# PIC32MK1024GPK064 device description
Architecture: MIPS; Family: PIC32MK; Series: PIC32MK
Registers are 32-bit, read-write, no defined reset value unless marked. A register's access mark holds for its fields unless they carry their own. Offsets are from the block's base; [hi:lo] are bit positions; 'fields as' and 'values as' point back to an identical list.

## RTCC
Instances: RTCC 0x1f8c0000 in periph_pb6_std
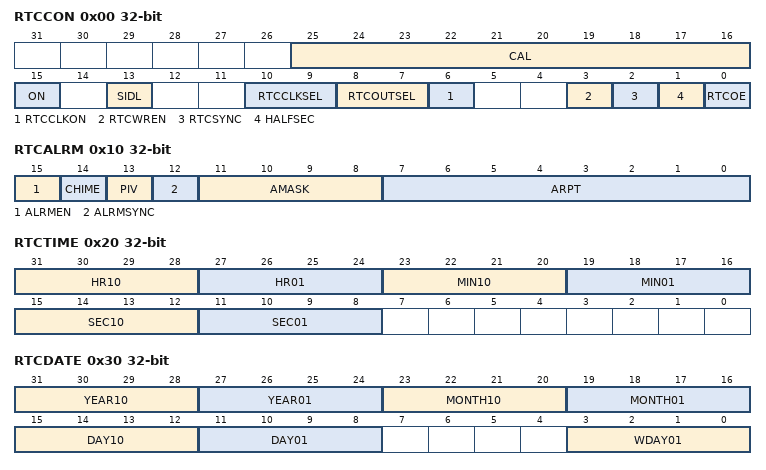
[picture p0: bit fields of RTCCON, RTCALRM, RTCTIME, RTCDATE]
0x00 RTCCON — Real-Time Clock and Calendar Control Register
  [25:16] CAL — Real-Time Clock Drift Calibration bits
    0x1ff=Maximum positive adjustment; 1=Minimum positive adjustment; 0=No adjustment; 0x3ff=Minimum negative adjustment; 0x200=Minimum negative adjustment
  [15] ON — RTCC On bit
    1=RTCC module is enabled; 0=RTCC module is disabled
  [13] SIDL — Stop in Idle Mode bit
    1=Disables RTCC operation when CPU enters Idle mode; 0=Continue normal operation when CPU enters Idle mode
  [10:9] RTCCLKSEL — RTCC Clock Select bits
    1=RTCC uses the external 32.768 kHz Secondary Oscillator (SOSC); 0=RTCC uses the internal 32 kHz oscillator (LPRC)
  [8:7] RTCOUTSEL — RTCC Output Data Select bits
    2=RTCC Clock is presented on the RTCC pin; 1=Seconds Clock is presented on the RTCC pin; 0=Alarm Pulse is presented on the RTCC pin when the alarm interrupt is triggered
  [6] RTCCLKON — RTCC Clock Enable Status bit
    1=RTCC Clock is actively running; 0=RTCC Clock is not running
  [3] RTCWREN — Real-Time Clock Value Registers Write Enable bit
    1=Real-Time Clock Value registers can be written to by the user; 0=Real-Time Clock Value registers are locked out from being written to by the user
  [2] RTCSYNC — Real-Time Clock Value Registers Read Synchronization bit
    1=Real-time clock value registers can change while reading (due to a rollover ripple that results in an invalid data read). If the register is read twice and results in the same data; 0=Real-time clock value registers can be read without concern about a rollover ripple
  [1] HALFSEC — Half-Second Status bit
    1=Second half period of a second; 0=First half period of a second
  [0] RTCOE — RTCC Output Enable bit
    1=RTCC output is enabled; 0=RTCC output is not enabled
0x10 RTCALRM — Real-Time Clock ALARM Control Register
  [15] ALRMEN — Alarm Enable bit
    1=Alarm is enabled; 0=Alarm is disabled
  [14] CHIME — Chime Enable bit
    1=Chime is enabled ARPT is allowed to rollover from 0x00 to 0xFF; 0=Chime is disabled ARPT stops once it reaches 0x00
  [13] PIV — Alarm Pulse Initial Value bit
    0=low initial value of the Alarm Pulse (When ALRMEN = 0); 1=high initial value of the Alarm Pulse (When ALRMEN = 0)
  [12] ALRMSYNC — Alarm Sync bit
    1=ARPT and ALRMEN may change as a result of a half second rollover during a read. The ARPT must be read repeatedly until the same value is read twice. This must be done since multiple bits may be changing.; 0=ARPT and ALRMEN can be read without concerns of rollover because the prescaler is more than 32 real-time clocks away from a half-second rollover
  [11:8] AMASK — Alarm Mask Configuration bits
    0=Every half-second; 1=Every second; 2=Every 10 seconds; 3=Every minute; 4=Every 10 minutes; 5=Every hour; 6=Once a day; 7=Once a week; 8=Once a month; 9=Once a year (except when configured for February 29
  [7:0] ARPT — Alarm Repeat Counter Value bits
    255=Alarm will trigger 256 times; 254=Alarm will trigger 255 times; 1=Alarm will trigger two times; 0=Alarm will trigger one time
0x20 RTCTIME — Real-Time Clock Time Value Register
  [31:28] HR10, [27:24] HR01, [23:20] MIN10, [19:16] MIN01, [15:12] SEC10, [11:8] SEC01
0x30 RTCDATE — Real-Time Clock Date Value Register
  [31:28] YEAR10, [27:24] YEAR01, [23:20] MONTH10, [19:16] MONTH01, [15:12] DAY10, [11:8] DAY01, [3:0] WDAY01
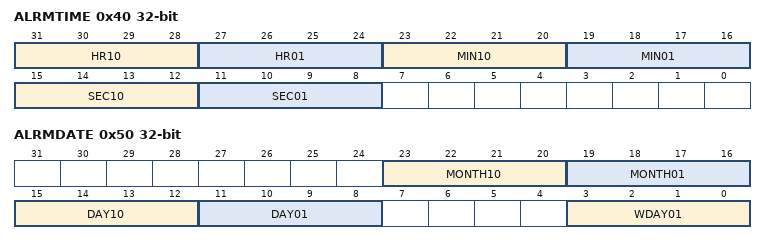
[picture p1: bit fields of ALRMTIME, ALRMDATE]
0x40 ALRMTIME — Alarm Time Value Register
  fields as RTCTIME
0x50 ALRMDATE — Alarm Date Value Register
  [23:20] MONTH10, [19:16] MONTH01, [15:12] DAY10, [11:8] DAY01, [3:0] WDAY01

## TMR1
Instances: TMR1 0x1f820000 in periph_pb2_std
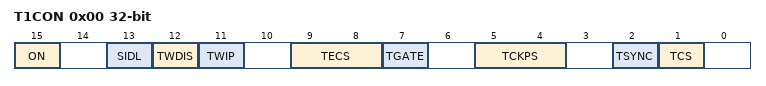
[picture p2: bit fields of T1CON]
0x00 T1CON — TYPE A TIMER CONTROL REGISTER
  [15] ON — Timer On bit
    1=Timer is enabled; 0=Timer is disabled
  [13] SIDL — Stop in Idle Mode bit
    1=Discontinue operation when device enters Idle mode; 0=Continue operation even in Idle mode
  [12] TWDIS — Asynchronous Timer Write Disable bit
    1=Writes to TMR1 are ignored until pending write operation completes; 0=Back-to-back writes are enabled (Legacy Asynchronous Timer functionality)
  [11] TWIP — Asynchronous Timer Write in Progress bit
    1=(In Asynchronous Timer mode) Asynchronous write to TMR1 register in progress / (In Synchronous Timer mode)bit is read as 0; 0=(In Asynchronous Timer mode) Asynchronous write to TMR1 register complete / (In Synchronous Timer mode)bit is read as 0
  [9:8] TECS — Timer1 External Clock Selection bits
    2=External clock comes from the LPRC; 1=External clock comes from the T1CK pin; 0=External clock comes from the SOSC
  [7] TGATE — Timer Gated Time Accumulation Enable bit
    1=(When TCS is 0) Gated time accumulation is enabled / (When TCS is 1) bit is ignored; 0=(When TCS is 0) Gated time accumulation is disabled / (When TCS is 1) bit is ignored
  [5:4] TCKPS — Timer Input Clock Prescale Select bits
    3=1:256 prescale value; 2=1:64 prescale value; 1=1:8 prescale value; 0=1:1 prescale value
  [2] TSYNC — Timer External Clock Input Synchronization Selection bit
    1=(When TCS is 1) External clock input is synchronized / (When TCS is 0) This bit is ignored; 0=(When TCS is 1) External clock input is not synchronized / (When TCS is 0) This bit is ignored
  [1] TCS — Timer Clock Source Select bit
    1=External clock is defined by the TECS bits; 0=Internal peripheral clock
0x10 TMR1
0x20 PR1

## TMR
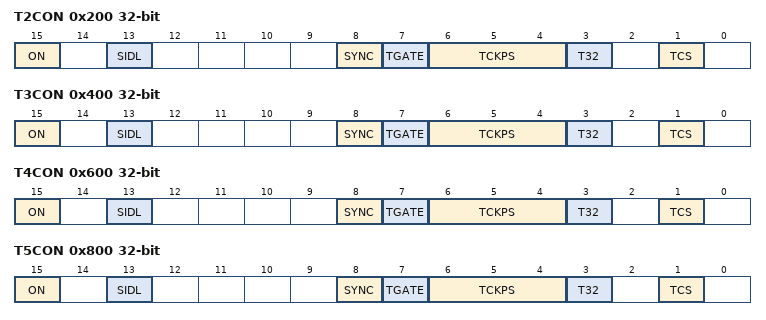
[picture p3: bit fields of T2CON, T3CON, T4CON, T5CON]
0x200 T2CON — Timer Configuration
  [15] ON — Timer On bit
    1=Module is enabled; 0=Module is disabled
  [13] SIDL — Stop in Idle Mode bit
    1=Discontinue operation when device enters Idle mode; 0=Continue operation even in Idle mode
  [8] SYNC — Synchronized Timer Start/Stop Enable bit
    1=Synchronized timer Start/Stop is enabled; 0=Synchronized timer Start/Stop is disabled
  [7] TGATE — Timer Gated Time Accumulation Enable bit
    1=(When TCS is 1) This bit is ignored and read as 0 / (When TCS is 0)Gated time accumulation is enabled; 0=(When TCS is 1) This bit is ignored and read as 0 / (When TCS is 0)Gated time accumulation is disabled
  [6:4] TCKPS — Timer Input Clock Prescale Select bits
    7=1:256 prescale value; 6=1:64 prescale value; 5=1:32 prescale value; 4=1:16 prescale value; 3=1:8 prescale value; 2=1:4 prescale value; 1=1:2 prescale value; 0=1:1 prescale value
  [3] T32 — 32-Bit Timer Mode Select bit
    1=32-bit Timer mode; 0=16-bit Timer mode
  [1] TCS — Timer Clock Source Select bit
    1=External clock from TxCK pin; 0=Internal peripheral clock
0x210 TMR2 — Timer
0x220 PR2 — Timer Period
0x400 T3CON — Timer Configuration
  fields as T2CON
0x410 TMR3 — Timer
0x420 PR3 — Timer Period
0x600 T4CON — Timer Configuration
  fields as T2CON
0x610 TMR4 — Timer
0x620 PR4 — Timer Period
0x800 T5CON — Timer Configuration
  fields as T2CON
0x810 TMR5 — Timer
0x820 PR5 — Timer Period
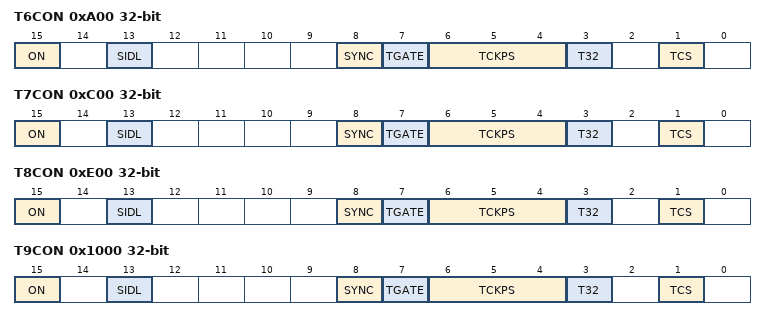
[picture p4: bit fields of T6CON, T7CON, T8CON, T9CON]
0xA00 T6CON — Timer Configuration
  fields as T2CON
0xA10 TMR6 — Timer
0xA20 PR6 — Timer Period
0xC00 T7CON — Timer Configuration
  fields as T2CON
0xC10 TMR7 — Timer
0xC20 PR7 — Timer Period
0xE00 T8CON — Timer Configuration
  fields as T2CON
0xE10 TMR8 — Timer
0xE20 PR8 — Timer Period
0x1000 T9CON — Timer Configuration
  fields as T2CON
0x1010 TMR9 — Timer
0x1020 PR9 — Timer Period

## WDT
Instances: WDT 0x1f800c00 in periph_pb1_std
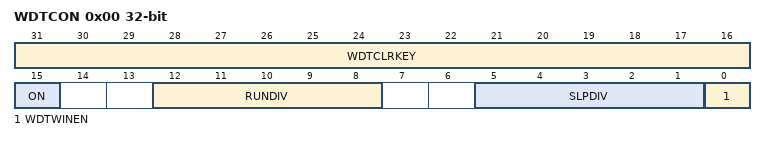
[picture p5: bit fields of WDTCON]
0x00 WDTCON — Watchdog Timer Control Register
  [31:16] WDTCLRKEY
  [15] ON — Watchdog Timer Enable bit
    1=The WDT is enabled; 0=The WDT is disabled
  [12:8] RUNDIV
  [5:1] SLPDIV
  [0] WDTWINEN — Watchdog Timer Window Enable bit
    1=Enable windowed Watchdog Timer; 0=Disable windowed Watchdog Timer
